AUTOSAR XML (schema 4-0-3)
standard types defined: Boolean, UInt32, UInt8
package /AUTOSAR_Platform/DataConstrs
  range DC_Boolean: raw 0..1
  range DC_UInt8: raw 0..255
package /PATAC/MSM/ComponentTypes
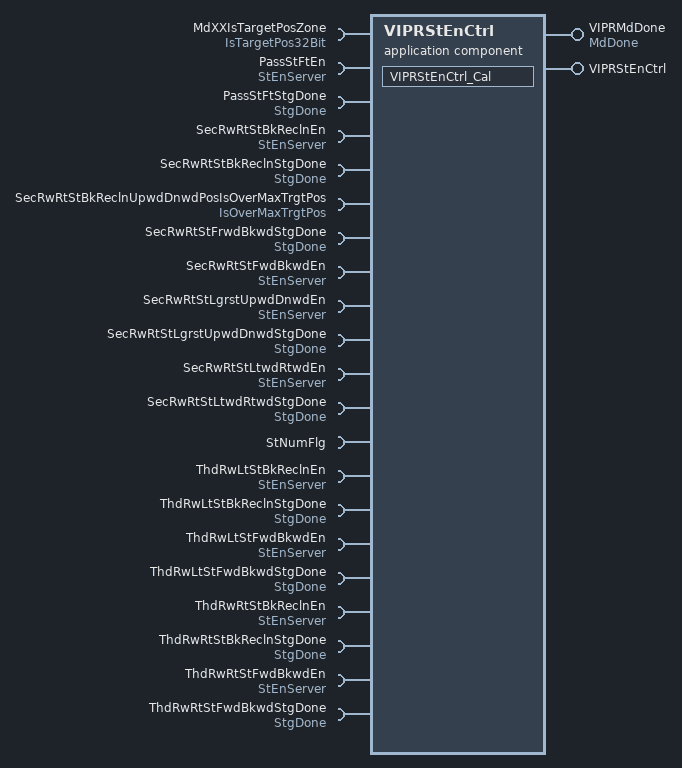
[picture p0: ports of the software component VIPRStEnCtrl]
  application sw component type VIPRStEnCtrl
    provide port VIPRMdDone: nonqueued-sender-com-spec{data-element=MdDone/Val, init-value=0}, provided-interface=MdDone
    provide port VIPRStEnCtrl: server-com-spec{operation=Cal, queue-length=1}, provided-interface=VIPRStEnCtrl
    21 x require port:
      MdXXIsTargetPosZone: nonqueued-receiver-com-spec{data-element=IsTargetPos32Bit/Val, filter=data-filter-type=ALWAYS, init-value=0}, required-interface=IsTargetPos32Bit
      PassStFtEn: required-com-specs=[Clear, Get, Set], required-interface=StEnServer
      PassStFtStgDone: nonqueued-receiver-com-spec{data-element=StgDone/Val, filter=data-filter-type=ALWAYS, init-value=0}, required-interface=StgDone
      SecRwRtStBkReclnEn: required-com-specs=[Clear, Get, Set], required-interface=StEnServer
      SecRwRtStBkReclnStgDone: nonqueued-receiver-com-spec{data-element=StgDone/Val, filter=data-filter-type=ALWAYS, init-value=0}, required-interface=StgDone
      SecRwRtStBkReclnUpwdDnwdPosIsOverMaxTrgtPos: nonqueued-receiver-com-spec{data-element=IsOverMaxTrgtPos/Val, filter=data-filter-type=ALWAYS, init-value=0}, required-interface=IsOverMaxTrgtPos
      SecRwRtStFrwdBkwdStgDone: nonqueued-receiver-com-spec{data-element=StgDone/Val, filter=data-filter-type=ALWAYS, init-value=0}, required-interface=StgDone
      SecRwRtStFwdBkwdEn: required-com-specs=[Clear, Get, Set], required-interface=StEnServer
      SecRwRtStLgrstUpwdDnwdEn: required-com-specs=[Clear, Get, Set], required-interface=StEnServer
      SecRwRtStLgrstUpwdDnwdStgDone: nonqueued-receiver-com-spec{data-element=StgDone/Val, filter=data-filter-type=ALWAYS, init-value=0}, required-interface=StgDone
      SecRwRtStLtwdRtwdEn: required-com-specs=[Clear, Get, Set], required-interface=StEnServer
      SecRwRtStLtwdRtwdStgDone: nonqueued-receiver-com-spec{data-element=StgDone/Val, filter=data-filter-type=ALWAYS, init-value=0}, required-interface=StgDone
      StNumFlg: required-interface=StNumFlg
        required-com-specs:
          data-element=Is4s, filter=data-filter-type=ALWAYS, init-value=0
          data-element=Is6s, filter=data-filter-type=ALWAYS, init-value=0
          data-element=Is6s7s, filter=data-filter-type=ALWAYS, init-value=0
          data-element=Is7s, filter=data-filter-type=ALWAYS, init-value=0
      ThdRwLtStBkReclnEn: required-com-specs=[Clear, Get, Set], required-interface=StEnServer
      ThdRwLtStBkReclnStgDone: nonqueued-receiver-com-spec{data-element=StgDone/Val, filter=data-filter-type=ALWAYS, init-value=0}, required-interface=StgDone
      ThdRwLtStFwdBkwdEn: required-com-specs=[Clear, Get, Set], required-interface=StEnServer
      ThdRwLtStFwdBkwdStgDone: nonqueued-receiver-com-spec{data-element=StgDone/Val, filter=data-filter-type=ALWAYS, init-value=0}, required-interface=StgDone
      ThdRwRtStBkReclnEn: required-com-specs=[Clear, Get, Set], required-interface=StEnServer
      ThdRwRtStBkReclnStgDone: nonqueued-receiver-com-spec{data-element=StgDone/Val, filter=data-filter-type=ALWAYS, init-value=0}, required-interface=StgDone
      ThdRwRtStFwdBkwdEn: required-com-specs=[Clear, Get, Set], required-interface=StEnServer
      ThdRwRtStFwdBkwdStgDone: nonqueued-receiver-com-spec{data-element=StgDone/Val, filter=data-filter-type=ALWAYS, init-value=0}, required-interface=StgDone
    behavior VIPRStEnCtrl_InternalBehavior
      operation invoked event OIT_VIPRStEnCtrl_Cal_VIPRStEnCtrl_Cal: start-on-event=VIPRStEnCtrl_Cal, operation=VIPRStEnCtrl.Cal
      runnable VIPRStEnCtrl_Cal
        data-receive-point-by-arguments:
          15 x access:
            REC_MdXXIsTargetPosZone_Val: accessed-variable=MdXXIsTargetPosZone.Val
            REC_PassStFtStgDone_Val: accessed-variable=PassStFtStgDone.Val
            REC_SecRwRtStBkReclnStgDone_Val: accessed-variable=SecRwRtStBkReclnStgDone.Val
            REC_SecRwRtStBkReclnUpwdDnwdPosIsOverMaxTrgtPos_Val: accessed-variable=SecRwRtStBkReclnUpwdDnwdPosIsOverMaxTrgtPos.Val
            REC_SecRwRtStFrwdBkwdStgDone_Val: accessed-variable=SecRwRtStFrwdBkwdStgDone.Val
            REC_SecRwRtStLgrstUpwdDnwdStgDone_Val: accessed-variable=SecRwRtStLgrstUpwdDnwdStgDone.Val
            REC_SecRwRtStLtwdRtwdStgDone_Val: accessed-variable=SecRwRtStLtwdRtwdStgDone.Val
            REC_StNumFlg_Is4s: accessed-variable=StNumFlg.Is4s
            REC_StNumFlg_Is6s: accessed-variable=StNumFlg.Is6s
            REC_StNumFlg_Is6s7s: accessed-variable=StNumFlg.Is6s7s
            REC_StNumFlg_Is7s: accessed-variable=StNumFlg.Is7s
            REC_ThdRwLtStBkReclnStgDone_Val: accessed-variable=ThdRwLtStBkReclnStgDone.Val
            REC_ThdRwLtStFwdBkwdStgDone_Val: accessed-variable=ThdRwLtStFwdBkwdStgDone.Val
            REC_ThdRwRtStBkReclnStgDone_Val: accessed-variable=ThdRwRtStBkReclnStgDone.Val
            REC_ThdRwRtStFwdBkwdStgDone_Val: accessed-variable=ThdRwRtStFwdBkwdStgDone.Val
        data-send-points:
          access SEND_VIPRMdDone_Val: accessed-variable=VIPRMdDone.Val
        18 x sync call, all with timeout=0:
          SC_PassStFtEn_Clear: operation=PassStFtEn.Clear
          SC_PassStFtEn_Set: operation=PassStFtEn.Set
          SC_SecRwRtStBkReclnEn_Clear: operation=SecRwRtStBkReclnEn.Clear
          SC_SecRwRtStBkReclnEn_Set: operation=SecRwRtStBkReclnEn.Set
          SC_SecRwRtStFwdBkwdEn_Clear: operation=SecRwRtStFwdBkwdEn.Clear
          SC_SecRwRtStFwdBkwdEn_Set: operation=SecRwRtStFwdBkwdEn.Set
          SC_SecRwRtStLgrstUpwdDnwdEn_Clear: operation=SecRwRtStLgrstUpwdDnwdEn.Clear
          SC_SecRwRtStLgrstUpwdDnwdEn_Set: operation=SecRwRtStLgrstUpwdDnwdEn.Set
          SC_SecRwRtStLtwdRtwdEn_Clear: operation=SecRwRtStLtwdRtwdEn.Clear
          SC_SecRwRtStLtwdRtwdEn_Set: operation=SecRwRtStLtwdRtwdEn.Set
          SC_ThdRwLtStBkReclnEn_Clear: operation=ThdRwLtStBkReclnEn.Clear
          SC_ThdRwLtStBkReclnEn_Set: operation=ThdRwLtStBkReclnEn.Set
          SC_ThdRwLtStFwdBkwdEn_Clear: operation=ThdRwLtStFwdBkwdEn.Clear
          SC_ThdRwLtStFwdBkwdEn_Set: operation=ThdRwLtStFwdBkwdEn.Set
          SC_ThdRwRtStBkReclnEn_Clear: operation=ThdRwRtStBkReclnEn.Clear
          SC_ThdRwRtStBkReclnEn_Set: operation=ThdRwRtStBkReclnEn.Set
          SC_ThdRwRtStFwdBkwdEn_Clear: operation=ThdRwRtStFwdBkwdEn.Clear
          SC_ThdRwRtStFwdBkwdEn_Set: operation=ThdRwRtStFwdBkwdEn.Set
  swc implementation VIPRStEnCtrl_Implementation: behavior=VIPRStEnCtrl_InternalBehavior
    code-descriptors:
      code Default: artifact-descriptors=autosar-engineering-object={short-label=Default, category=SWSRC}
package /PATAC/MSM/ModeAdjust/PortInterface
  client server interface StEnServer
    operation Clear
      arg data: type=UInt8, direction=IN, server-argument-impl-policy=USE-ARGUMENT-TYPE
    operation Get
      arg data: type=UInt32, direction=OUT, server-argument-impl-policy=USE-ARGUMENT-TYPE
    operation Set
      arg data: type=UInt8, direction=IN, server-argument-impl-policy=USE-ARGUMENT-TYPE
  client server interface VIPRStEnCtrl
    operation Cal
  4 x sender receiver interface:
    IsTargetPos32Bit: invalidation-policy{data-element=IsTargetPos32Bit/Val, handle-invalid=DONT-INVALIDATE}
      data Val: type=UInt32
    MdDone: invalidation-policy{data-element=MdDone/Val, handle-invalid=DONT-INVALIDATE}
      data Val: type=UInt8
    StgDone: invalidation-policy{data-element=StgDone/Val, handle-invalid=DONT-INVALIDATE}
      data Val: type=Boolean
    StNumFlg
      4 x data, all with type=Boolean:
        Is4s
        Is6s
        Is6s7s
        Is7s
      invalidation-policys:
        data-element=Is7s, handle-invalid=DONT-INVALIDATE
        data-element=Is6s, handle-invalid=DONT-INVALIDATE
        data-element=Is4s, handle-invalid=DONT-INVALIDATE
        data-element=Is6s7s, handle-invalid=DONT-INVALIDATE
package /PortInterfaces
  sender receiver interface IsOverMaxTrgtPos: invalidation-policy{data-element=IsOverMaxTrgtPos/Val, handle-invalid=DONT-INVALIDATE}
    data Val: type=Boolean
